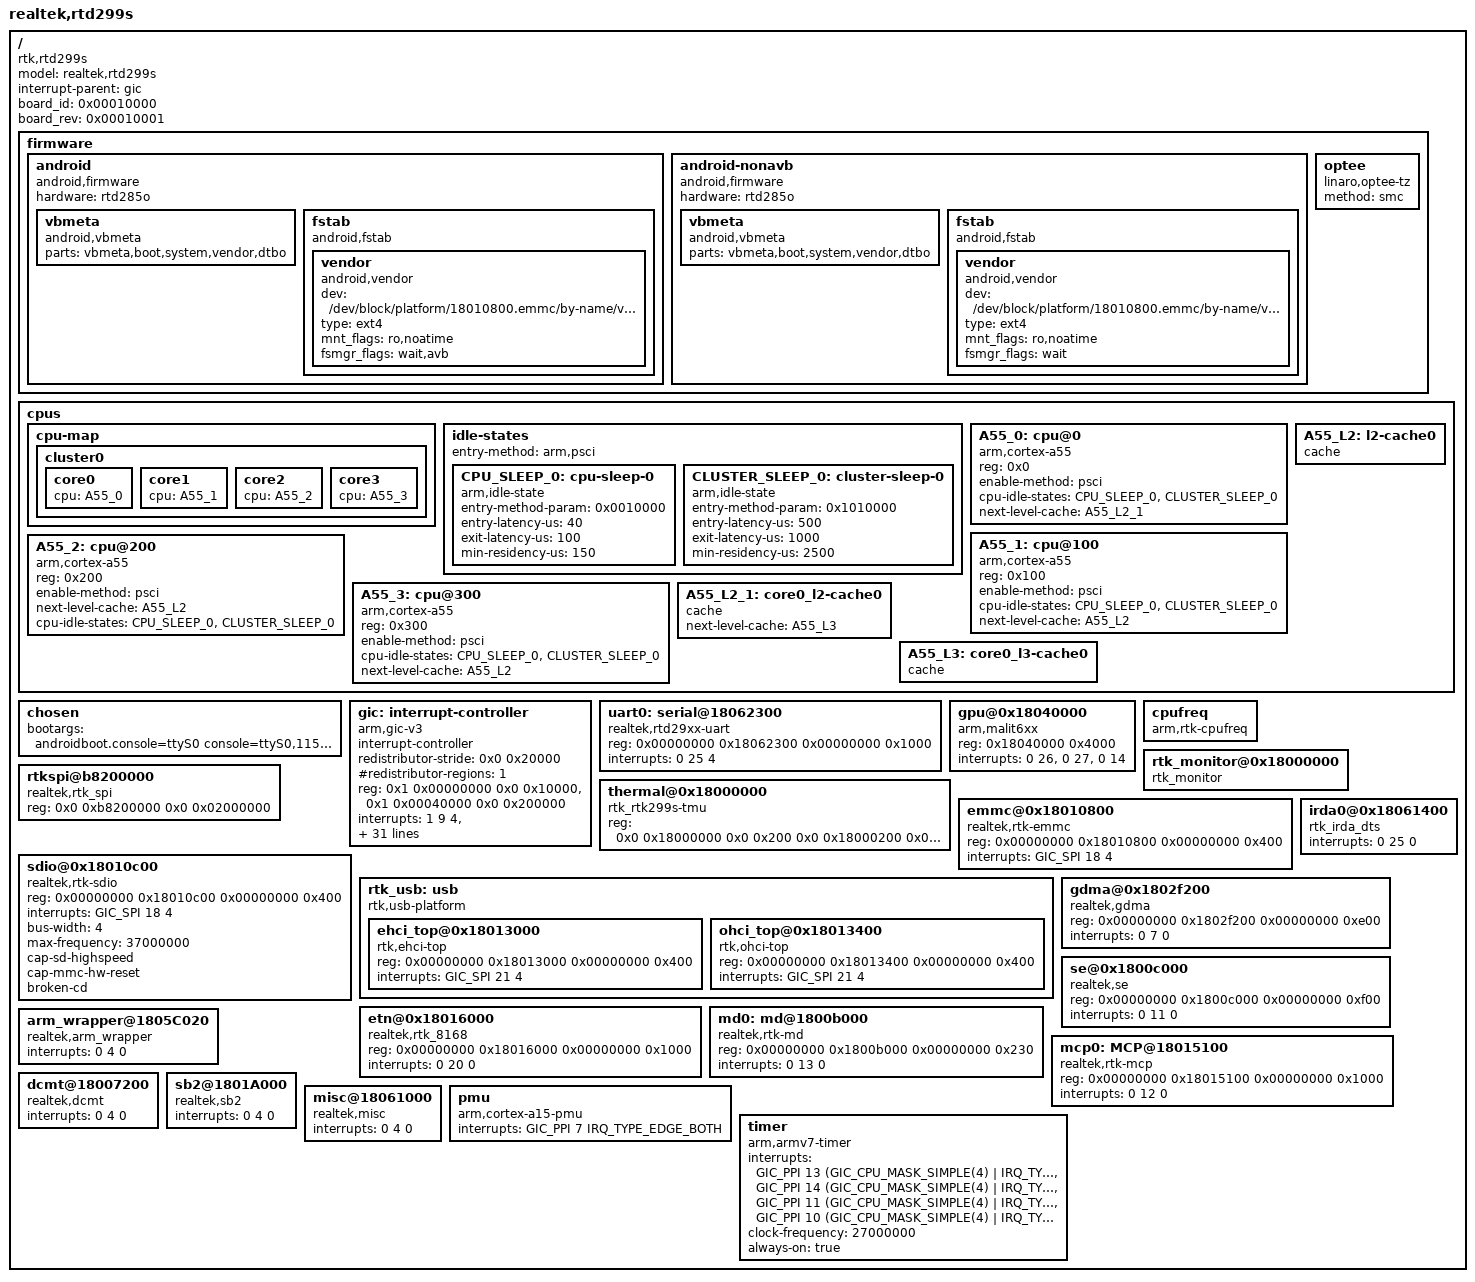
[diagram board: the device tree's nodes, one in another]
/*
 * rtd299s device tree source
 *
*/

#include <dt-bindings/interrupt-controller/irq.h>
#include <dt-bindings/interrupt-controller/arm-gic.h>


/dts-v1/;
/include/ "skeleton.dtsi"

/ {
	model = "realtek,rtd299s";
	compatible = "rtk,rtd299s";
	interrupt-parent = <&gic>;
        #address-cells = <2>;
        #size-cells = <2>;
	board_id = <0x00010000>;
	board_rev = <0x00010001>;


    firmware {
        android {
            compatible = "android,firmware";
            hardware = "rtd285o";
            vbmeta {
                compatible = "android,vbmeta";
                parts = "vbmeta,boot,system,vendor,dtbo";
            };
            fstab {
                compatible = "android,fstab";
                vendor {
                    compatible = "android,vendor";
                    dev = "/dev/block/platform/18010800.emmc/by-name/vendor";
                    type = "ext4";
                    mnt_flags = "ro,noatime";
                    fsmgr_flags = "wait,avb";
                };
            };
        };
    };

    firmware {
        android-nonavb {
            compatible = "android,firmware";
            hardware = "rtd285o";
            vbmeta {
                compatible = "android,vbmeta";
                parts = "vbmeta,boot,system,vendor,dtbo";
            };
            fstab {
                compatible = "android,fstab";
                vendor {
                    compatible = "android,vendor";
                    dev = "/dev/block/platform/18010800.emmc/by-name/vendor";
                    type = "ext4";
                    mnt_flags = "ro,noatime";
                    fsmgr_flags = "wait";
                };
            };
        };
    };

	cpus {
		#address-cells = <0x1>;
		#size-cells = <0>;

		cpu-map {
			cluster0: cluster0 {
				#cooling-cells = <2>; /* min followed by max */

				core0 {
					cpu = <&A55_0>;
				};
				core1 {
					cpu = <&A55_1>;
				};
				core2 {
					cpu = <&A55_2>;
				};
				core3 {
					cpu = <&A55_3>;
				};
			};

		};

		idle-states {
			entry-method = "arm,psci";

			CPU_SLEEP_0: cpu-sleep-0 {
				compatible = "arm,idle-state";
				entry-method-param = <0x0010000>;
				entry-latency-us = <40>;
				exit-latency-us = <100>;
				min-residency-us = <150>;
			};

			CLUSTER_SLEEP_0: cluster-sleep-0 {
				compatible = "arm,idle-state";
				entry-method-param = <0x1010000>;
				entry-latency-us = <500>;
				exit-latency-us = <1000>;
				min-residency-us = <2500>;
			};
		};

		A55_0: cpu@0 {
			compatible = "arm,cortex-a55","arm,armv8";
			reg = <0x0>;
			device_type = "cpu";
			enable-method = "psci";
			cpu-idle-states = <&CPU_SLEEP_0 &CLUSTER_SLEEP_0>;
                        next-level-cache = <&A55_L2_1>;
			clock-names = "vlittle";
		};
		A55_1: cpu@100 {
			compatible = "arm,cortex-a55","arm,armv8";
			reg = <0x100>;
			device_type = "cpu";
			enable-method = "psci";
			cpu-idle-states = <&CPU_SLEEP_0 &CLUSTER_SLEEP_0>;
                        next-level-cache = <&A55_L2>;
			clock-names = "vlittle";
		};
		A55_2: cpu@200 {
			compatible = "arm,cortex-a55","arm,armv8";
			reg = <0x200>;
			device_type = "cpu";
			enable-method = "psci";
                        next-level-cache = <&A55_L2>;
			cpu-idle-states = <&CPU_SLEEP_0 &CLUSTER_SLEEP_0>;
			clock-names = "vlittle";
		};

		A55_3: cpu@300 {
			compatible = "arm,cortex-a55","arm,armv8";
			reg = <0x300>;
			device_type = "cpu";
			enable-method = "psci";
			cpu-idle-states = <&CPU_SLEEP_0 &CLUSTER_SLEEP_0>;
                        next-level-cache = <&A55_L2>;
			clock-names = "vlittle";
		};

                A55_L2: l2-cache0 {
                        compatible = "cache";
                };

                A55_L2_1: core0_l2-cache0 {
                        compatible = "cache";
                        next-level-cache = <&A55_L3>;
                };

                A55_L3: core0_l3-cache0 {
                        compatible = "cache";
                };
	};


//	memory {
//		reg = <0x00000000 0x10000000>; /* 512MB */
//	};

	firmware {
		optee {
			compatible = "linaro,optee-tz";
			method = "smc";
		};
	};

	chosen {
		bootargs ="androidboot.console=ttyS0 console=ttyS0,115200 envp=100700 flashtype=emmc mmcparts=rtkemmc:3358720k,524288k(/system),1572864k(/data),524288k(/cache),16384k(/res) earlyprintk ac_on ac_on root=/dev/mmcblk0p1 rootfstype=ext4 ro rootwait";
	};

	gic:interrupt-controller {
                compatible = "arm,gic-v3";
                #interrupt-cells = <0x3>;
                #address-cells = <0x2>;
                #size-cells = <0x2>;
                interrupt-controller;
                redistributor-stride = <0x0 0x20000>;
                #redistributor-regions = <1>;
                reg = <0x1 0x00000000 0x0 0x10000>,       // GICD
                      <0x1 0x00040000 0x0 0x200000>;      // GICR
		interrupts = <1 9 4>,
		<GIC_PPI 13 IRQ_TYPE_LEVEL_LOW>,
                <GIC_PPI 14 IRQ_TYPE_LEVEL_LOW>,
                <GIC_PPI 11 IRQ_TYPE_LEVEL_LOW>,
                <GIC_PPI 10 IRQ_TYPE_LEVEL_LOW>,
		<GIC_SPI 0 4>, <GIC_SPI 1 4>,<GIC_SPI 2 4>,<GIC_SPI 3 4>,<GIC_SPI 4 4>,<GIC_SPI 5 4>, <GIC_SPI 6 4>,<GIC_SPI 7 4>,<GIC_SPI 8 4>,<GIC_SPI 9 4>,
		<GIC_SPI 10 4>, <GIC_SPI 11 4>,<GIC_SPI 12 4>,<GIC_SPI 13 4>,<GIC_SPI 14 4>,<GIC_SPI 15 4>, <GIC_SPI 16 4>,<GIC_SPI 17 4>,<GIC_SPI 18 4>,<GIC_SPI 19 4>,
		<GIC_SPI 20 4>, <GIC_SPI 21 4>,<GIC_SPI 22 4>,<GIC_SPI 23 4>,<GIC_SPI 24 4>,<GIC_SPI 25 4>, <GIC_SPI 26 4>,<GIC_SPI 27 4>,<GIC_SPI 28 4>,<GIC_SPI 29 4>,
		<GIC_SPI 30 4>, <GIC_SPI 31 4>,<GIC_SPI 32 4>,<GIC_SPI 33 4>,<GIC_SPI 34 4>,<GIC_SPI 35 4>, <GIC_SPI 36 4>,<GIC_SPI 37 4>,<GIC_SPI 38 4>,<GIC_SPI 39 4>,
		<GIC_SPI 40 4>, <GIC_SPI 41 4>,<GIC_SPI 42 4>,<GIC_SPI 43 4>,<GIC_SPI 44 4>,<GIC_SPI 45 4>, <GIC_SPI 46 4>,<GIC_SPI 47 4>,<GIC_SPI 48 4>,<GIC_SPI 49 4>,
		<GIC_SPI 50 4>, <GIC_SPI 51 4>,<GIC_SPI 52 4>,<GIC_SPI 53 4>,<GIC_SPI 54 4>,<GIC_SPI 55 4>, <GIC_SPI 56 4>,<GIC_SPI 57 4>,<GIC_SPI 58 4>,<GIC_SPI 59 4>,
		<GIC_SPI 60 4>, <GIC_SPI 61 4>,<GIC_SPI 62 4>,<GIC_SPI 63 4>,<GIC_SPI 64 4>,<GIC_SPI 65 4>, <GIC_SPI 66 4>,<GIC_SPI 67 4>,<GIC_SPI 68 4>,<GIC_SPI 69 4>,
		<GIC_SPI 70 4>, <GIC_SPI 71 4>,<GIC_SPI 72 4>,<GIC_SPI 73 4>,<GIC_SPI 74 4>,<GIC_SPI 75 4>, <GIC_SPI 76 4>,<GIC_SPI 77 4>,<GIC_SPI 78 4>,<GIC_SPI 79 4>;

	};

	uart0: serial@18062300 {
        	#address-cells = <2>;
        	#size-cells = <2>;
		compatible = "realtek,rtd29xx-uart";
		reg = <0x00000000 0x18062300 0x00000000 0x1000>;
		interrupts = <0 25 4>;
	};

	gpu@0x18040000 {
		compatible = "arm,malit6xx", "arm,mali-midgard";
		reg = <0x18040000 0x4000>;
		interrupts = <0 26>, <0 27>, <0 14>;
		interrupt-names = "JOB", "MMU", "GPU";

		//clocks = <&pclk_mali>;
		clock-names = "clk_mali";
	};

        cpufreq {
                compatible = "arm,rtk-cpufreq";
        };

	thermal@0x18000000 {
        	compatible = "rtk_rtk299s-tmu";
        	reg = <0x0 0x18000000 0x0 0x200
        	       0x0 0x18000200 0x0 0x200>;
        	status = "okay";
        };

        rtk_monitor@0x18000000 {
                compatible = "rtk_monitor";
                status = "okay";
        };
        
	rtkspi@b8200000 {
		#address-cells = <2>;
                #size-cells = <2>;
		compatible = "realtek,rtk_spi";
		reg = <0x0 0xb8200000 0x0 0x02000000>;
        };
        
	emmc@0x18010800 {
        	#address-cells = <1>;
        	#size-cells = <1>;
		compatible = "realtek,rtk-emmc";
		reg = <0x00000000 0x18010800 0x00000000 0x400>;
		interrupts = <GIC_SPI 18 4>;
	};

	sdio@0x18010c00 {
		compatible = "realtek,rtk-sdio";
		reg = <0x00000000 0x18010c00 0x00000000 0x400>;
		interrupts = <GIC_SPI 18 4>;
		bus-width = <4>;
		max-frequency = <37000000>;
		cap-sd-highspeed;
		cap-mmc-hw-reset;
		broken-cd;
	};

	rtk_usb: usb {
		compatible = "rtk,usb-platform";
		#address-cells = <2>;
		#size-cells = <2>;
		ranges;

		ehci_top@0x18013000 {
			compatible = "rtk,ehci-top";
			reg = <0x00000000 0x18013000 0x00000000 0x400>;  /* 64bit address <<address> <size>> */
			interrupts = <GIC_SPI 21 4>;
		};

		ohci_top@0x18013400 {
			compatible = "rtk,ohci-top";
			reg = <0x00000000 0x18013400 0x00000000 0x400>;
			interrupts = <GIC_SPI 21 4>;
		};
	};


//        clock-controller@0x18000350 {
//               compatible = "realtek,rtd299s-clock";
//                reg = <0x18000350 0x4b0>;
//                #clock-cells = <1>;
//        };

	irda0@0x18061400 {
		compatible = "rtk_irda_dts";
		interrupts = < 0 25 0 >;
		//interrupts = < 0 31 0 >;
	};

	gdma@0x1802f200 {
		#address-cells = <2>;
		#size-cells = <2>;
		device_type = "osd";
		compatible = "realtek,gdma";
		reg = <0x00000000 0x1802f200 0x00000000 0xe00>;
		interrupts = <0 7 0>;
	};

	se@0x1800c000 {
		#address-cells = <2>;
		#size-cells = <2>;
		device_type = "2dgraphic";
		compatible = "realtek,se";
		reg = <0x00000000 0x1800c000 0x00000000 0xf00>;
		interrupts = <0 11 0>;
	};

	etn@0x18016000 {
		compatible = "realtek,rtk_8168";
		reg = <0x00000000 0x18016000 0x00000000 0x1000>;
		interrupts = <0 20 0>;
	};
	
        md0:md@1800b000 {
		compatible = "realtek,rtk-md";
		reg = <0x00000000 0x1800b000 0x00000000 0x230>;
		interrupts = <0 13 0>;
	};

	mcp0:MCP@18015100 {
		compatible = "realtek,rtk-mcp";
		reg = <0x00000000 0x18015100 0x00000000 0x1000>;
		interrupts = <0 12 0>;
	};

        arm_wrapper@1805C020 {
                compatible = "realtek,arm_wrapper";
                interrupts = <0 4 0>;
        };

        dcmt@18007200 {
                compatible = "realtek,dcmt";
                interrupts = <0 4 0>;
        };

        sb2@1801A000 {
                compatible = "realtek,sb2";
                interrupts = <0 4 0>;
        };

        misc@18061000 {
                compatible = "realtek,misc";
                interrupts = <0 4 0>;
        };

	pmu {
		compatible = "arm,cortex-a15-pmu";
//		interrupts = <GIC_SPI 31 IRQ_TYPE_EDGE_BOTH>;
		interrupts = <GIC_PPI  7 IRQ_TYPE_EDGE_BOTH>; // PPI 23
	};

	timer {
		compatible = "arm,armv7-timer";
		interrupts = <GIC_PPI 13 (GIC_CPU_MASK_SIMPLE(4) | IRQ_TYPE_LEVEL_LOW)>,
			<GIC_PPI 14 (GIC_CPU_MASK_SIMPLE(4) | IRQ_TYPE_LEVEL_LOW)>,
			<GIC_PPI 11 (GIC_CPU_MASK_SIMPLE(4) | IRQ_TYPE_LEVEL_LOW)>,
			<GIC_PPI 10 (GIC_CPU_MASK_SIMPLE(4) | IRQ_TYPE_LEVEL_LOW)>;
		clock-frequency = <27000000>;
		always-on = "true";
	};
};
